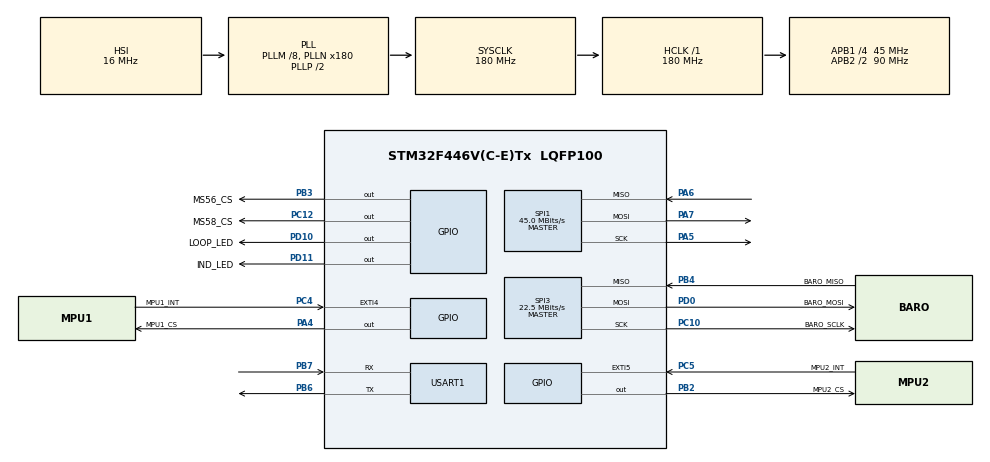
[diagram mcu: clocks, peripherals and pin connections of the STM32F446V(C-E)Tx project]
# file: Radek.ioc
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Dma.Request0=SPI3_RX
Dma.Request1=SPI3_TX
Dma.Request2=SPI1_RX
Dma.Request3=SPI1_TX
Dma.SPI1_RX.2.Direction=DMA_PERIPH_TO_MEMORY
Dma.SPI1_RX.2.FIFOMode=DMA_FIFOMODE_DISABLE
Dma.SPI1_RX.2.Instance=DMA2_Stream0
Dma.SPI1_RX.2.MemDataAlignment=DMA_MDATAALIGN_BYTE
Dma.SPI1_RX.2.MemInc=DMA_MINC_ENABLE
Dma.SPI1_RX.2.Mode=DMA_NORMAL
Dma.SPI1_RX.2.PeriphDataAlignment=DMA_PDATAALIGN_BYTE
Dma.SPI1_RX.2.PeriphInc=DMA_PINC_DISABLE
Dma.SPI1_RX.2.Priority=DMA_PRIORITY_LOW
Dma.SPI1_TX.3.Direction=DMA_MEMORY_TO_PERIPH
Dma.SPI1_TX.3.FIFOMode=DMA_FIFOMODE_DISABLE
Dma.SPI1_TX.3.Instance=DMA2_Stream3
Dma.SPI1_TX.3.MemDataAlignment=DMA_MDATAALIGN_BYTE
Dma.SPI1_TX.3.MemInc=DMA_MINC_ENABLE
Dma.SPI1_TX.3.Mode=DMA_NORMAL
Dma.SPI1_TX.3.PeriphDataAlignment=DMA_PDATAALIGN_BYTE
Dma.SPI1_TX.3.PeriphInc=DMA_PINC_DISABLE
Dma.SPI1_TX.3.Priority=DMA_PRIORITY_LOW
Dma.SPI3_RX.0.Direction=DMA_PERIPH_TO_MEMORY
Dma.SPI3_RX.0.FIFOMode=DMA_FIFOMODE_DISABLE
Dma.SPI3_RX.0.Instance=DMA1_Stream0
Dma.SPI3_RX.0.MemDataAlignment=DMA_MDATAALIGN_BYTE
Dma.SPI3_RX.0.MemInc=DMA_MINC_ENABLE
Dma.SPI3_RX.0.Mode=DMA_NORMAL
Dma.SPI3_RX.0.PeriphDataAlignment=DMA_PDATAALIGN_BYTE
Dma.SPI3_RX.0.PeriphInc=DMA_PINC_DISABLE
Dma.SPI3_RX.0.Priority=DMA_PRIORITY_LOW
Dma.SPI3_TX.1.Direction=DMA_MEMORY_TO_PERIPH
Dma.SPI3_TX.1.FIFOMode=DMA_FIFOMODE_DISABLE
Dma.SPI3_TX.1.Instance=DMA1_Stream5
Dma.SPI3_TX.1.MemDataAlignment=DMA_MDATAALIGN_BYTE
Dma.SPI3_TX.1.MemInc=DMA_MINC_ENABLE
Dma.SPI3_TX.1.Mode=DMA_NORMAL
Dma.SPI3_TX.1.PeriphDataAlignment=DMA_PDATAALIGN_BYTE
Dma.SPI3_TX.1.PeriphInc=DMA_PINC_DISABLE
Dma.SPI3_TX.1.Priority=DMA_PRIORITY_LOW
Mcu.Family=STM32F4
Mcu.Name=STM32F446V(C-E)Tx
Mcu.Package=LQFP100
NVIC.DMA1_Stream0_IRQn=true\:5\:0\:true\:false\:true\:false\:true
NVIC.DMA1_Stream5_IRQn=true\:5\:0\:true\:false\:true\:false\:true
NVIC.DMA2_Stream0_IRQn=true\:5\:0\:true\:false\:true\:false\:true
NVIC.DMA2_Stream3_IRQn=true\:5\:0\:true\:false\:true\:false\:true
NVIC.EXTI9_5_IRQn=true\:5\:0\:true\:false\:true\:true\:true
NVIC.PriorityGroup=NVIC_PRIORITYGROUP_4
NVIC.SPI1_IRQn=true\:5\:0\:true\:false\:true\:true\:true
NVIC.SPI3_IRQn=true\:5\:0\:true\:false\:true\:true\:true
NVIC.TIM8_TRG_COM_TIM14_IRQn=true\:0\:0\:false\:false\:true\:true\:true
NVIC.TIM8_UP_TIM13_IRQn=true\:0\:0\:false\:false\:true\:false\:true
NVIC.TimeBase=TIM8_UP_TIM13_IRQn
NVIC.TimeBaseIP=TIM13
NVIC.USART1_IRQn=true\:5\:0\:true\:false\:true\:true\:true
PA4.GPIO_Label=MPU1_CS
PA4.Signal=GPIO_Output
PA5.Mode=Full_Duplex_Master
PA5.Signal=SPI1_SCK
PA6.Mode=Full_Duplex_Master
PA6.Signal=SPI1_MISO
PA7.Mode=Full_Duplex_Master
PA7.Signal=SPI1_MOSI
PB2.GPIO_Label=MPU2_CS
PB2.Signal=GPIO_Output
PB3.GPIO_Label=MS56_CS
PB3.Signal=GPIO_Output
PB4.GPIO_Label=BARO_MISO
PB4.Mode=Full_Duplex_Master
PB4.Signal=SPI3_MISO
PB6.Mode=Asynchronous
PB6.Signal=USART1_TX
PB7.Mode=Asynchronous
PB7.Signal=USART1_RX
PC10.GPIO_Label=BARO_SCLK
PC10.Mode=Full_Duplex_Master
PC10.Signal=SPI3_SCK
PC12.GPIO_Label=MS58_CS
PC12.Signal=GPIO_Output
PC4.GPIO_Label=MPU1_INT
PC4.Signal=GPXTI4
PC5.GPIO_Label=MPU2_INT
PC5.Signal=GPXTI5
PD0.GPIO_Label=BARO_MOSI
PD0.Mode=Full_Duplex_Master
PD0.Signal=SPI3_MOSI
PD10.GPIO_Label=LOOP_LED
PD10.Signal=GPIO_Output
PD11.GPIO_Label=IND_LED
PD11.Signal=GPIO_Output
ProjectManager.HeapSize=0x200
ProjectManager.StackSize=0x400
ProjectManager.TargetToolchain=SW4STM32
RCC.AHBFreq_Value=180000000
RCC.APB1CLKDivider=RCC_HCLK_DIV4
RCC.APB1Freq_Value=45000000
RCC.APB1TimFreq_Value=90000000
RCC.APB2CLKDivider=RCC_HCLK_DIV2
RCC.APB2Freq_Value=90000000
RCC.APB2TimFreq_Value=180000000
RCC.CortexFreq_Value=180000000
RCC.HCLKFreq_Value=180000000
RCC.PLLM=8
RCC.PLLN=180
RCC.SYSCLKFreq_VALUE=180000000
RCC.SYSCLKSource=RCC_SYSCLKSOURCE_PLLCLK
RCC.USBFreq_Value=180000000
RCC.VCOOutputFreq_Value=360000000
SPI1.CalculateBaudRate=45.0 MBits/s
SPI1.Direction=SPI_DIRECTION_2LINES
SPI1.Mode=SPI_MODE_MASTER
SPI1.VirtualType=VM_MASTER
SPI3.CalculateBaudRate=22.5 MBits/s
SPI3.Direction=SPI_DIRECTION_2LINES
SPI3.Mode=SPI_MODE_MASTER
SPI3.VirtualType=VM_MASTER
USART1.VirtualMode=VM_ASYNC
VP_SYS_VS_tim13.Mode=TIM13
VP_TIM14_VS_ClockSourceINT.Mode=Enable_Timer
board=custom

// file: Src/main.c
/* USER CODE BEGIN Header */
/**
  ******************************************************************************
  * @file           : main.c
  * @brief          : Main program body
  ******************************************************************************
  * @attention
  *
  * <h2><center>&copy; Copyright (c) 2020 STMicroelectronics.
  * All rights reserved.</center></h2>
  *
  * This software component is licensed by ST under BSD 3-Clause license,
  * the "License"; You may not use this file except in compliance with the
  * License. You may obtain a copy of the License at:
  *                        opensource.org/licenses/BSD-3-Clause
  *
  ******************************************************************************
  */
/* USER CODE END Header */

#include "main.h"
#include "dma.h"
#include "spi.h"
#include "tim.h"
#include "usart.h"
#include "gpio.h"

/* USER CODE BEGIN Includes */
#include "SS_console.h"
#include "SS_log.h"
#include "SS_common.h"
#include "SS_platform.h"

//to clean later:
/* USER CODE END Includes */

void SystemClock_Config(void);

int main(void)
{

  /* MCU Configuration--------------------------------------------------------*/

  /* Reset of all peripherals, Initializes the Flash interface and the Systick. */
  HAL_Init();

  /* Configure the system clock */
  SystemClock_Config();

  /* Initialize all configured peripherals */
  MX_GPIO_Init();
  MX_DMA_Init();
  MX_USART1_UART_Init();
  MX_TIM14_Init();
  MX_SPI3_Init();
  MX_SPI1_Init();
  /* USER CODE BEGIN 2 */
  SS_platform_init();
  SS_init();
  /* USER CODE END 2 */

  /* Infinite loop */
  /* USER CODE BEGIN WHILE */
  while (1)
  {
//      HAL_GPIO_TogglePin(LOOP_IND_GPIO_Port, LOOP_IND_Pin);
//      HAL_Delay(100);
    /* USER CODE END WHILE */

  }
}

void SystemClock_Config(void)
{
  RCC_OscInitTypeDef RCC_OscInitStruct = {0};
  RCC_ClkInitTypeDef RCC_ClkInitStruct = {0};

  /** Configure the main internal regulator output voltage
  */
  __HAL_RCC_PWR_CLK_ENABLE();
  __HAL_PWR_VOLTAGESCALING_CONFIG(PWR_REGULATOR_VOLTAGE_SCALE1);
  /** Initializes the CPU, AHB and APB busses clocks
  */
  RCC_OscInitStruct.OscillatorType = RCC_OSCILLATORTYPE_HSI;
  RCC_OscInitStruct.HSIState = RCC_HSI_ON;
  RCC_OscInitStruct.HSICalibrationValue = RCC_HSICALIBRATION_DEFAULT;
  RCC_OscInitStruct.PLL.PLLState = RCC_PLL_ON;
  RCC_OscInitStruct.PLL.PLLSource = RCC_PLLSOURCE_HSI;
  RCC_OscInitStruct.PLL.PLLM = 8;
  RCC_OscInitStruct.PLL.PLLN = 180;
  RCC_OscInitStruct.PLL.PLLP = RCC_PLLP_DIV2;
  RCC_OscInitStruct.PLL.PLLQ = 2;
  RCC_OscInitStruct.PLL.PLLR = 2;
  if (HAL_RCC_OscConfig(&RCC_OscInitStruct) != HAL_OK)
  {
    Error_Handler();
  }
  /** Activate the Over-Drive mode
  */
  if (HAL_PWREx_EnableOverDrive() != HAL_OK)
  {
    Error_Handler();
  }
  /** Initializes the CPU, AHB and APB busses clocks
  */
  RCC_ClkInitStruct.ClockType = RCC_CLOCKTYPE_HCLK|RCC_CLOCKTYPE_SYSCLK
                              |RCC_CLOCKTYPE_PCLK1|RCC_CLOCKTYPE_PCLK2;
  RCC_ClkInitStruct.SYSCLKSource = RCC_SYSCLKSOURCE_PLLCLK;
  RCC_ClkInitStruct.AHBCLKDivider = RCC_SYSCLK_DIV1;
  RCC_ClkInitStruct.APB1CLKDivider = RCC_HCLK_DIV4;
  RCC_ClkInitStruct.APB2CLKDivider = RCC_HCLK_DIV2;

  if (HAL_RCC_ClockConfig(&RCC_ClkInitStruct, FLASH_LATENCY_5) != HAL_OK)
  {
    Error_Handler();
  }
}

void HAL_TIM_PeriodElapsedCallback(TIM_HandleTypeDef *htim)
{
  if (htim->Instance == TIM13) {
    HAL_IncTick();
  }
}

void Error_Handler(void)
{
}

/************************ (C) COPYRIGHT STMicroelectronics *****END OF FILE****/
